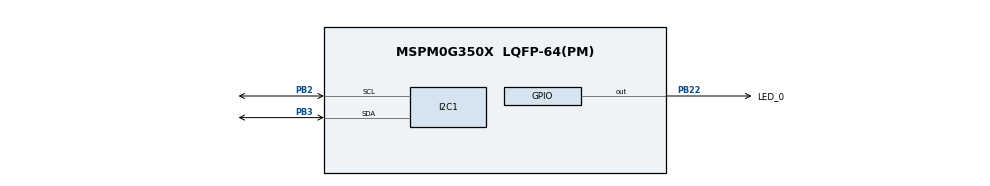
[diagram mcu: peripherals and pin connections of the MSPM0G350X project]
/**
 * @cliArgs --device "MSPM0G350X" --part "Default" --package "LQFP-64(PM)" --product "mspm0_sdk@2.11.00.07"
 * @versions {"tool":"1.26.2+4477"}
 */

/**
 * Import the modules used in this configuration.
 */
const GPIO   = scripting.addModule("/ti/driverlib/GPIO", {}, false);
const GPIO1  = GPIO.addInstance();
const I2C    = scripting.addModule("/ti/driverlib/I2C", {}, false);
const I2C1   = I2C.addInstance();
const SYSCTL = scripting.addModule("/ti/driverlib/SYSCTL");

/**
 * Write custom configuration values to the imported modules.
 */
const divider9       = system.clockTree["UDIV"];
divider9.divideValue = 2;

const multiplier2         = system.clockTree["PLL_QDIV"];
multiplier2.multiplyValue = 4;

const mux4       = system.clockTree["EXHFMUX"];
mux4.inputSelect = "EXHFMUX_XTAL";

const mux8       = system.clockTree["HSCLKMUX"];
mux8.inputSelect = "HSCLKMUX_SYSPLL0";

const mux12       = system.clockTree["SYSPLLMUX"];
mux12.inputSelect = "zSYSPLLMUX_HFCLK";

const pinFunction4     = system.clockTree["HFXT"];
pinFunction4.inputFreq = 40;
pinFunction4.enable    = true;

GPIO1.$name                         = "LED";
GPIO1.associatedPins[0].$name       = "LED_0";
GPIO1.associatedPins[0].pin.$assign = "PB22";

const Board = scripting.addModule("/ti/driverlib/Board", {}, false);

I2C1.$name                             = "OLED";
I2C1.basicEnableController             = true;
I2C1.advDigitalGlitchFilter            = "CLOCKS_1";
I2C1.advControllerRXFIFOTRIG           = "BYTES_8";
I2C1.advControllerTXFIFOTRIG           = "BYTES_7";
I2C1.enableDMAEvent1                   = false;
I2C1.enableDMAEvent2                   = false;
I2C1.basicControllerStandardBusSpeed   = "Standard";
I2C1.peripheral.$assign                = "I2C1";
I2C1.peripheral.sdaPin.$assign         = "PB3";
I2C1.peripheral.sclPin.$assign         = "PB2";
I2C1.sdaPinConfig.$name                = "ti_driverlib_gpio_GPIOPinGeneric0";
I2C1.sdaPinConfig.hideOutputInversion  = scripting.forceWrite(false);
I2C1.sdaPinConfig.onlyInternalResistor = scripting.forceWrite(false);
I2C1.sdaPinConfig.passedPeripheralType = scripting.forceWrite("Digital");
I2C1.sdaPinConfig.enableConfig         = true;
I2C1.sdaPinConfig.internalResistor     = "PULL_UP";
I2C1.sclPinConfig.$name                = "ti_driverlib_gpio_GPIOPinGeneric1";
I2C1.sclPinConfig.hideOutputInversion  = scripting.forceWrite(false);
I2C1.sclPinConfig.onlyInternalResistor = scripting.forceWrite(false);
I2C1.sclPinConfig.passedPeripheralType = scripting.forceWrite("Digital");
I2C1.sclPinConfig.enableConfig         = true;
I2C1.sclPinConfig.internalResistor     = "PULL_UP";

SYSCTL.forceDefaultClkConfig = true;
SYSCTL.clockTreeEn           = true;

/**
 * Pinmux solution for unlocked pins/peripherals. This ensures that minor changes to the automatic solver in a future
 * version of the tool will not impact the pinmux you originally saw.  These lines can be completely deleted in order to
 * re-solve from scratch.
 */
pinFunction4.peripheral.$suggestSolution           = "SYSCTL";
pinFunction4.peripheral.hfxInPin.$suggestSolution  = "PA5";
pinFunction4.peripheral.hfxOutPin.$suggestSolution = "PA6";
Board.peripheral.$suggestSolution                  = "DEBUGSS";
Board.peripheral.swclkPin.$suggestSolution         = "PA20";
Board.peripheral.swdioPin.$suggestSolution         = "PA19";
